AUTOSAR XML (schema 4-2-2)
package /AUTOLIV/SoftwareComponents/ATM
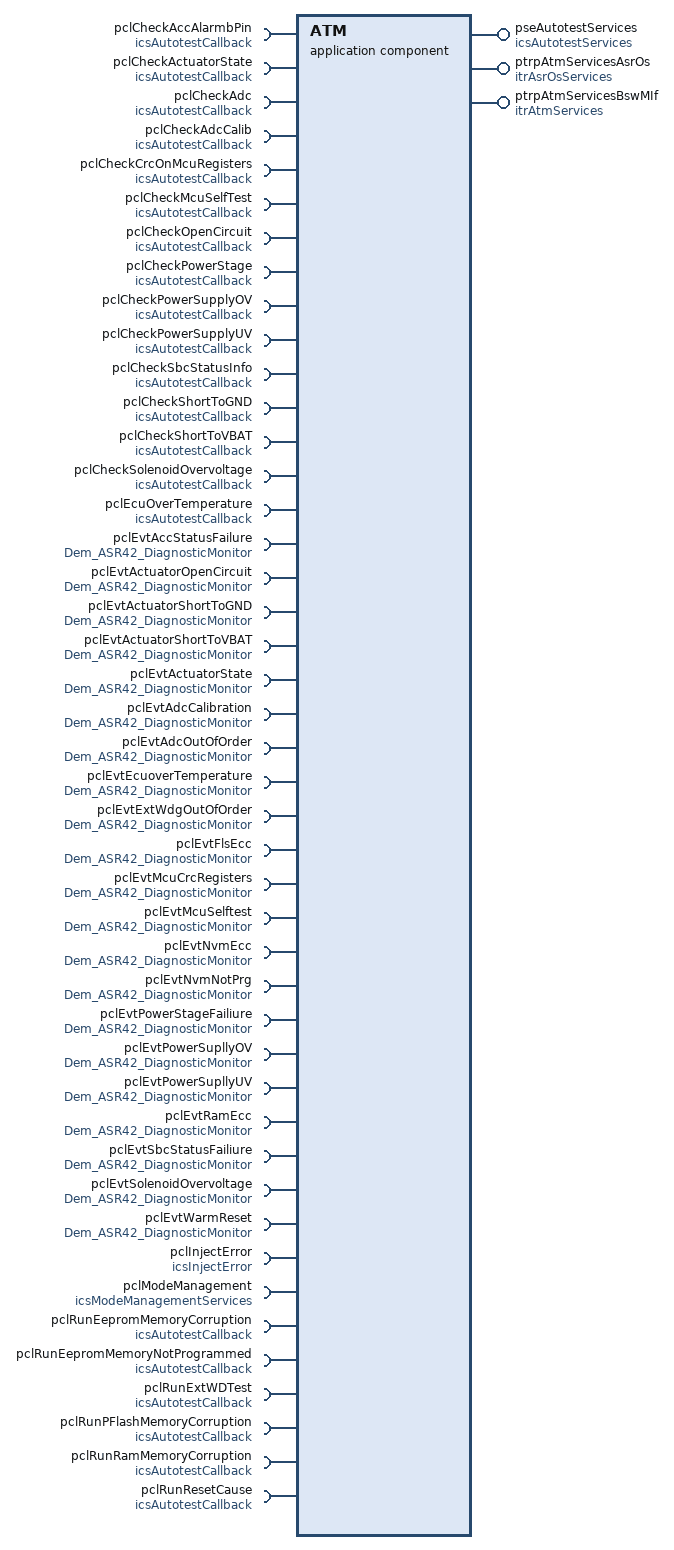
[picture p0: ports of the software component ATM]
  application sw component type ATM: category=SWC  # ATM_AC_AutoTestManager
    44 x require port:
      pclCheckAccAlarmbPin: client-com-spec=AutotestCallback, required-interface=icsAutotestCallback  # # Architecture Element ID ARCH_SW_pclCheckAccAlarmbPin # Description - The interface shall be used to check if the ALARMB pin of the TDK accelerometer chip has been activated. # Data Flow ## Inputs: - {Autotest Result} - Can be one of the following values: OK,NOK,NOT DECIDED ## Outputs - {Autotest Result} - Can be one of the following values: OK,NOK,NOT DECIDED # Linked Runnable - ATM_runMainFunction # Traceability
      pclCheckActuatorState: client-com-spec=AutotestCallback, required-interface=icsAutotestCallback  # # Architecture Element ID ARCH_SW_pclCheckActuatorState # Description - The interface shall be used to check if solenoids has been activated successfully. # Data Flow ## Inputs: - {Autotest Result} - Can be one of the following values: OK,NOK,NOT DECIDED ## Outputs - {Autotest Result} - Can be one of the following values: OK,NOK,NOT DECIDED # Linked Runnable - ATM_runMainFunction # Traceability
      pclCheckAdc: client-com-spec=AutotestCallback, required-interface=icsAutotestCallback  # # Architecture Element ID ARCH_SW_pclCheckAdc # Description - The interface shall be used to check if the two reference voltages measured on the dedicated ADC channels do not drift. # Data Flow ## Inputs: - {Autotest Result} - Can be one of the following values: OK,NOK,NOT DECIDED ## Outputs - {Autotest Result} - Can be one of the following values: OK,NOK,NOT DECIDED # Linked Runnable - ATM_runMainFunction # Traceability FUSA_SM_S32K1XXSM_302
      pclCheckAdcCalib: client-com-spec=AutotestCallback, required-interface=icsAutotestCallback  # # Architecture Element ID ARCH_SW_pclCheckAdcCalib # Description - The interface shall be used to check if the ADC calibration is OK # Data Flow ## Inputs: - {Autotest Result} - Can be one of the following values: OK,NOK,NOT DECIDED ## Outputs - {Autotest Result} - Can be one of the following values: OK,NOK,NOT DECIDED # Linked Runnable - ATM_runMainFunction # Traceability
      pclCheckCrcOnMcuRegisters: client-com-spec=AutotestCallback, required-interface=icsAutotestCallback  # # Architecture Element ID ARCH_SW_pclCheckCrcOnMcuRegisters # Description - The interface shall be used to check CRC on PORT, ADC and FTM MCU registers. # Data Flow ## Inputs: - {Autotest Result} - Can be one of the following values: OK,NOK,NOT DECIDED ## Outputs - {Autotest Result} - Can be one of the following values: OK,NOK,NOT DECIDED # Linked Runnable - ATM_runMainFunction # Traceability
      pclCheckMcuSelfTest: client-com-spec=AutotestCallback, required-interface=icsAutotestCallback  # # Architecture Element ID ARCH_SW_pclCheckMcuSelfTest # Description - The interface shall be used to check internal hardware logic of the MCU. # Data Flow ## Inputs: - {Autotest Result} - Can be one of the following values: OK,NOK,NOT DECIDED ## Outputs - {Autotest Result} - Can be one of the following values: OK,NOK,NOT DECIDED # Linked Runnable - ATM_runMainFunction # Traceability
      pclCheckOpenCircuit: client-com-spec=AutotestCallback, required-interface=icsAutotestCallback  # # Architecture Element ID ARCH_SW_pclCheckOpenCircuit # Description - The interface shall be used to check an open circuit fault on each solenoid circuit. # Data Flow ## Inputs: - {Autotest Result} - Can be one of the following values: OK,NOK,NOT DECIDED ## Outputs - {Autotest Result} - Can be one of the following values: OK,NOK,NOT DECIDED # Linked Runnable - ATM_runMainFunction # Traceability
      pclCheckPowerStage: client-com-spec=AutotestCallback, required-interface=icsAutotestCallback  # # Architecture Element ID ARCH_SW_pclCheckPowerStage # Description - The interface shall be used to check if power stage is functioning correctly. # Data Flow ## Inputs: - {Autotest Result} - Can be one of the following values: OK,NOK,NOT DECIDED ## Outputs - {Autotest Result} - Can be one of the following values: OK,NOK,NOT DECIDED # Linked Runnable - ATM_runMainFunction # Traceability
      pclCheckPowerSupplyOV: client-com-spec=AutotestCallback, required-interface=icsAutotestCallback  # # Architecture Element ID ARCH_SW_pclCheckPowerSupplyOV # Description - The interface shall be used to check for overvoltage on the Power stage battery voltage. # Data Flow ## Inputs: - {Autotest Result} - Can be one of the following values: OK,NOK,NOT DECIDED ## Outputs - {Autotest Result} - Can be one of the following values: OK,NOK,NOT DECIDED # Linked Runnable - ATM_runMainFunction # Traceability
      pclCheckPowerSupplyUV: client-com-spec=AutotestCallback, required-interface=icsAutotestCallback  # # Architecture Element ID ARCH_SW_pclCheckPowerSupplyUV # Description - The interface shall be used to check for undervoltage on the Power stage battery voltage. # Data Flow ## Inputs: - {Autotest Result} - Can be one of the following values: OK,NOK,NOT DECIDED ## Outputs - {Autotest Result} - Can be one of the following values: OK,NOK,NOT DECIDED # Linked Runnable - ATM_runMainFunction # Traceability
      pclCheckSbcStatusInfo: client-com-spec=AutotestCallback, required-interface=icsAutotestCallback  # # Architecture Element ID ARCH_SW_pclCheckSbcStatusInfo # Description - The interface shall be used to check if the the Status information section of a Spi response from the SBC chip. # Data Flow ## Inputs: - {Autotest Result} - Can be one of the following values: OK,NOK,NOT DECIDED ## Outputs - {Autotest Result} - Can be one of the following values: OK,NOK,NOT DECIDED # Linked Runnable - ATM_runMainFunction # Traceability
      pclCheckShortToGND: client-com-spec=AutotestCallback, required-interface=icsAutotestCallback  # # Architecture Element ID ARCH_SW_pclCheckShortToGND # Description - The interface shall be used to check a short-to-ground fault on each solenoid circuit. # Data Flow ## Inputs: - {Autotest Result} - Can be one of the following values: OK,NOK,NOT DECIDED ## Outputs - {Autotest Result} - Can be one of the following values: OK,NOK,NOT DECIDED # Linked Runnable - ATM_runMainFunction # Traceability
      pclCheckShortToVBAT: client-com-spec=AutotestCallback, required-interface=icsAutotestCallback  # # Architecture Element ID ARCH_SW_pclCheckShortToVBAT # Description - The interface shall be used to check a short-to-VBAT fault on each solenoid circuit. # Data Flow ## Inputs: - {Autotest Result} - Can be one of the following values: OK,NOK,NOT DECIDED ## Outputs - {Autotest Result} - Can be one of the following values: OK,NOK,NOT DECIDED # Linked Runnable - ATM_runMainFunction # Traceability
      pclCheckSolenoidOvervoltage: client-com-spec=AutotestCallback, required-interface=icsAutotestCallback  # # Architecture Element ID ARCH_SW_pclCheckSolenoidOvervoltage # Description - The interface shall be used to check that no overvoltage condition is present on the solenoids. # Data Flow ## Inputs: - {Autotest Result} - Can be one of the following values: OK,NOK,NOT DECIDED ## Outputs - {Autotest Result} - Can be one of the following values: OK,NOK,NOT DECIDED # Linked Runnable - ATM_runMainFunction # Traceability
      pclEcuOverTemperature: client-com-spec=AutotestCallback, required-interface=icsAutotestCallback  # # Architecture Element ID ARCH_SW_pclEcuOverTemperature # Description - The interface shall be used to check over temperature of MCU. # Data Flow ## Inputs: - {Autotest Result} - Can be one of the following values: OK,NOK,NOT DECIDED ## Outputs - {Autotest Result} - Can be one of the following values: OK,NOK,NOT DECIDED # Linked Runnable - ATM_runMainFunction # Traceability
      pclEvtAccStatusFailure: required-com-specs=[SetEventStatus, ResetEventStatus, ResetEventDebounceStatus, PrestoreFreezeFrame, ClearPrestoredFreezeFrame], required-interface=Dem_ASR42_DiagnosticMonitor
      pclEvtActuatorOpenCircuit: required-com-specs=[SetEventStatus, ResetEventStatus, ResetEventDebounceStatus, PrestoreFreezeFrame, ClearPrestoredFreezeFrame], required-interface=Dem_ASR42_DiagnosticMonitor
      pclEvtActuatorShortToGND: required-com-specs=[SetEventStatus, ResetEventStatus, ResetEventDebounceStatus, PrestoreFreezeFrame, ClearPrestoredFreezeFrame], required-interface=Dem_ASR42_DiagnosticMonitor
      pclEvtActuatorShortToVBAT: required-com-specs=[SetEventStatus, ResetEventStatus, ResetEventDebounceStatus, PrestoreFreezeFrame, ClearPrestoredFreezeFrame], required-interface=Dem_ASR42_DiagnosticMonitor
      pclEvtActuatorState: required-com-specs=[SetEventStatus, ResetEventStatus, ResetEventDebounceStatus, PrestoreFreezeFrame, ClearPrestoredFreezeFrame], required-interface=Dem_ASR42_DiagnosticMonitor
      pclEvtAdcCalibration: required-com-specs=[SetEventStatus, ResetEventStatus, ResetEventDebounceStatus, PrestoreFreezeFrame, ClearPrestoredFreezeFrame], required-interface=Dem_ASR42_DiagnosticMonitor
      pclEvtAdcOutOfOrder: required-com-specs=[SetEventStatus, ResetEventStatus, PrestoreFreezeFrame, ClearPrestoredFreezeFrame], required-interface=Dem_ASR42_DiagnosticMonitor
      pclEvtEcuoverTemperature: required-com-specs=[SetEventStatus, ResetEventStatus, ResetEventDebounceStatus, PrestoreFreezeFrame, ClearPrestoredFreezeFrame], required-interface=Dem_ASR42_DiagnosticMonitor
      pclEvtExtWdgOutOfOrder: required-com-specs=[SetEventStatus, ResetEventStatus, PrestoreFreezeFrame, ClearPrestoredFreezeFrame], required-interface=Dem_ASR42_DiagnosticMonitor
      pclEvtFlsEcc: required-com-specs=[SetEventStatus, ResetEventStatus, ResetEventDebounceStatus, PrestoreFreezeFrame, ClearPrestoredFreezeFrame], required-interface=Dem_ASR42_DiagnosticMonitor
      pclEvtMcuCrcRegisters: required-com-specs=[SetEventStatus, ResetEventStatus, ResetEventDebounceStatus, PrestoreFreezeFrame, ClearPrestoredFreezeFrame], required-interface=Dem_ASR42_DiagnosticMonitor
      pclEvtMcuSelftest: required-com-specs=[SetEventStatus, ResetEventStatus, ResetEventDebounceStatus, PrestoreFreezeFrame, ClearPrestoredFreezeFrame], required-interface=Dem_ASR42_DiagnosticMonitor
      pclEvtNvmEcc: required-com-specs=[SetEventStatus, ResetEventStatus, PrestoreFreezeFrame, ClearPrestoredFreezeFrame], required-interface=Dem_ASR42_DiagnosticMonitor
      pclEvtNvmNotPrg: required-com-specs=[SetEventStatus, ResetEventStatus, PrestoreFreezeFrame, ClearPrestoredFreezeFrame], required-interface=Dem_ASR42_DiagnosticMonitor
      pclEvtPowerStageFailiure: required-com-specs=[SetEventStatus, ResetEventStatus, ResetEventDebounceStatus, PrestoreFreezeFrame, ClearPrestoredFreezeFrame], required-interface=Dem_ASR42_DiagnosticMonitor
      pclEvtPowerSupllyOV: required-com-specs=[SetEventStatus, ResetEventStatus, ResetEventDebounceStatus, PrestoreFreezeFrame, ClearPrestoredFreezeFrame], required-interface=Dem_ASR42_DiagnosticMonitor
      pclEvtPowerSupllyUV: required-interface=Dem_ASR42_DiagnosticMonitor
      pclEvtRamEcc: required-com-specs=[SetEventStatus, ResetEventStatus, PrestoreFreezeFrame, ClearPrestoredFreezeFrame], required-interface=Dem_ASR42_DiagnosticMonitor
      pclEvtSbcStatusFailiure: required-com-specs=[SetEventStatus, ResetEventStatus, ResetEventDebounceStatus, PrestoreFreezeFrame, ClearPrestoredFreezeFrame], required-interface=Dem_ASR42_DiagnosticMonitor
      pclEvtSolenoidOvervoltage: required-com-specs=[SetEventStatus, ResetEventStatus, ResetEventDebounceStatus, PrestoreFreezeFrame, ClearPrestoredFreezeFrame], required-interface=Dem_ASR42_DiagnosticMonitor
      pclEvtWarmReset: required-com-specs=[SetEventStatus, ResetEventStatus, PrestoreFreezeFrame, ClearPrestoredFreezeFrame], required-interface=Dem_ASR42_DiagnosticMonitor
      pclInjectError: client-com-spec=EIM_ManageAecStatus, required-interface=icsInjectError  # # Architecture Element ID ARCH_SW_pclInjectError # Description - The interface shall be used to handle error event status for the EIM module if is enabled. # Data Flow ## Inputs: - {Autotest Result} - Can be one of the following values: B_TRUE, B_FALSE ## Outputs - {Autotest Result} - Can be one of the following values: B_TRUE, B_FALSE # Linked Runnable - ATM_runMainFunction # Traceability
      pclModeManagement: client-com-spec=CheckModeStatus, required-interface=icsModeManagementServices  # # Architecture Element ID ARCH_SW_ATM_pclModeManagement # Description - The interface shall be used to check running context service. It indicates whether all the required contextes are OK. (atm_executeAutoTest) # Data Flow ## Inputs: - {Autotest Result} - Can be one of the following values: B_TRUE, B_FALSE ## Outputs - {Autotest Result} - Can be one of the following values: B_TRUE, B_FALSE # Linked Runnable - ATM_runMainFunction # Traceability
      pclRunEepromMemoryCorruption: client-com-spec=AutotestCallback, required-interface=icsAutotestCallback  # # Architecture Element ID ARCH_SW_pclRunEepromMemoryCorruption # Description - The interface shall be used to check if an ECC was detected in DFLASH memory area. # Data Flow ## Inputs: - {Autotest Result} - Can be one of the following values: OK,NOK,NOT DECIDED ## Outputs - {Autotest Result} - Can be one of the following values: OK,NOK,NOT DECIDED # Linked Runnable - ATM_runMainFunction # Traceability
      pclRunEepromMemoryNotProgrammed: client-com-spec=AutotestCallback, required-interface=icsAutotestCallback  # # Architecture Element ID ARCH_SW_pclRunEepromMemoryNotProgrammed # Description - The interface shall be used to check if one or more EEPROM blocks are not programmed (Manufacture) # Data Flow ## Inputs: - {Autotest Result} - Can be one of the following values: OK,NOK,NOT DECIDED ## Outputs - {Autotest Result} - Can be one of the following values: OK,NOK,NOT DECIDED # Linked Runnable - ATM_runMainFunction # Traceability
      pclRunExtWDTest: client-com-spec=AutotestCallback, required-interface=icsAutotestCallback  # # Architecture Element ID ARCH_SW_pclEvtExtWdgOutOfOrder # Description - The interface shall be used to check the external WDG status # Data Flow ## Inputs: - {Autotest Result} - Can be one of the following values: OK,NOK ## Outputs - {Autotest Result} - Can be one of the following values: OK,NOK # Linked Runnable - ATM_runMainFunction # Traceability FUSA_SM_S32K1XXSM_539, FUSA_SM_S32K1XXSM_541
      pclRunPFlashMemoryCorruption: client-com-spec=AutotestCallback, required-interface=icsAutotestCallback  # # Architecture Element ID ARCH_SW_pclRunPFlashMemoryCorruption # Description - The interface shall be used to check if an ECC was detected in PFLASH memory area. # Data Flow ## Inputs: - {Autotest Result} - Can be one of the following values: OK,NOK,NOT DECIDED ## Outputs - {Autotest Result} - Can be one of the following values: OK,NOK,NOT DECIDED # Linked Runnable - ATM_runMainFunction # Traceability
      pclRunRamMemoryCorruption: client-com-spec=AutotestCallback, required-interface=icsAutotestCallback  # # Architecture Element ID ARCH_SW_pclRunRamMemoryCorruption # Description - The interface shall be used to check if an ECC was detected in RAM memory area. # Data Flow ## Inputs: - {Autotest Result} - Can be one of the following values: OK,NOK,NOT DECIDED ## Outputs - {Autotest Result} - Can be one of the following values: OK,NOK,NOT DECIDED # Linked Runnable - ATM_runMainFunction # Traceability
      pclRunResetCause: client-com-spec=AutotestCallback, required-interface=icsAutotestCallback  # # Architecture Element ID ARCH_SW_pclRunResetCause # Description - The interface shall be used to check if an unexpected reset cause has been detected. # Data Flow ## Inputs: - {Autotest Result} - Can be one of the following values: OK,NOK,NOT DECIDED ## Outputs - {Autotest Result} - Can be one of the following values: OK,NOK,NOT DECIDED # Linked Runnable - ATM_runMainFunction # Traceability
    provide port pseAutotestServices: provided-com-specs=[{operation=GetCriticalAutoTestsReachedFlag, queue-length=1}, {operation=GetTestResult, queue-length=1}], provided-interface=icsAutotestServices  # # Architecture Element ID ARCH_SW_pseAutotestServices_GetTestResult # Description - Get ADC auto-test result # Data Flow ## Inputs: - Test result from ATM_runGetTestResult ## Outputs - u8TestResult # Linked Runnable - ATM_runGetTestResult # Traceability #------------------------------------------------------------------------------------------------------------ # Architecture Element ID ARCH_SW_pseAutotestServices_GetCriticalAutoTestsReachedFlag # Description - The function aims at returning the auto test reached flag # Data Flow ## Inputs: - Test result from ATM_runGetTestResult ## Outputs - pb8CriticalAutoTestsFlag # Linked Runnable - ATM_runGetCriticalAutoTestsReachedFlag # Traceability
    provide port ptrpAtmServicesAsrOs: provided-interface=itrAsrOsServices  # # Architecture Element ID ARCH_SW_BswMIf_ptrpAtmServicesAsrOs_ATM_runMainFunction # Description - The ATM_runMainFunction runnable shall be called when the Os task {OsTask_Alv_Autotests} is executed # Data Flow # Linked Runnable - ATM_runMainFunction # Traceability DOM_eCS_TF_H_300 DOM_eCS_TF_H_301 DOM_eCS_TF_H_302 FUSA_SM_S32K1XXSM_452 DOM_eCS_TF_H_380 DOM_eCS_TF_H_377 DOM_eCS_TF_H_374 --------------------------------------------------------------------------------------------------------------------------------
    provide port ptrpAtmServicesBswMIf: provided-interface=itrAtmServices  # # Architecture Element ID ARCH_SW_Atm_ptrpAtmServicesBswMIf_ATM_runInit # Description - The ATM_Init runnable shall be called during the initialization in the BswM_OnStartComEffective runnable # Data Flow # Linked Runnable - ATM_Init # Traceability
